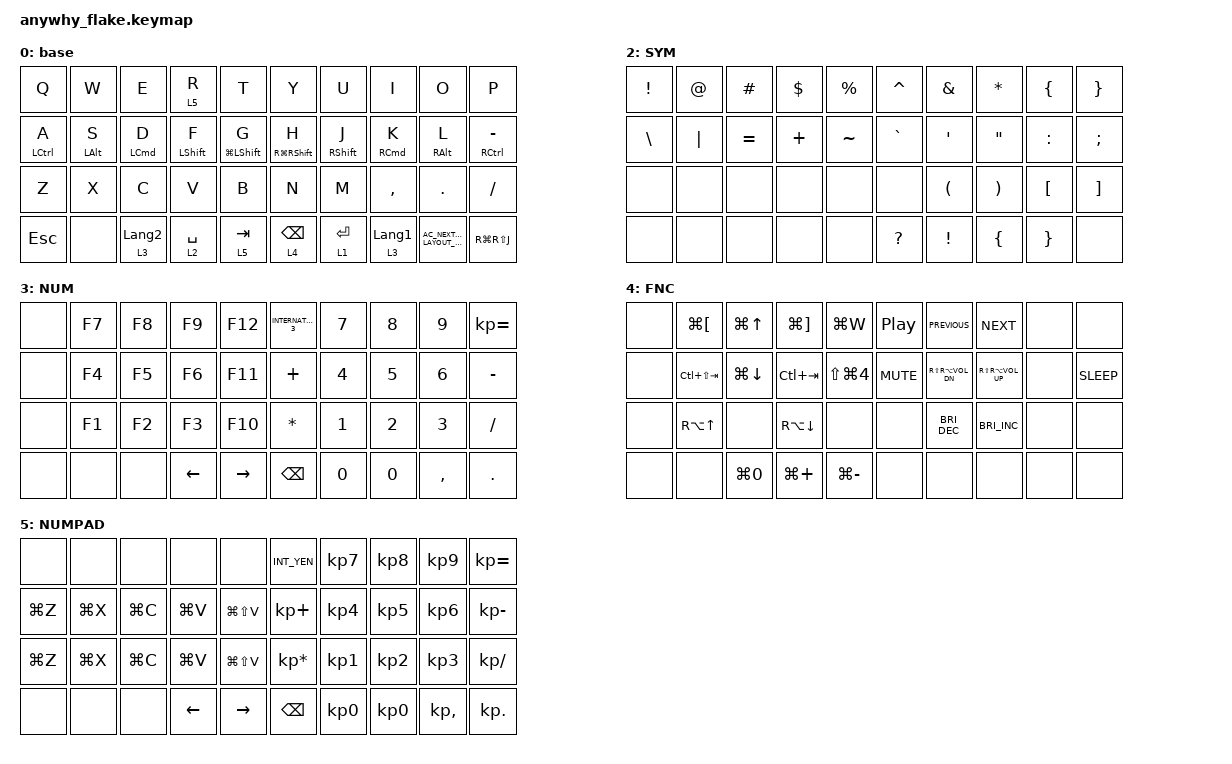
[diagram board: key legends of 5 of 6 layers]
#include <behaviors.dtsi>
#include <dt-bindings/zmk/bt.h>
#include <dt-bindings/zmk/keys.h>
#include <dt-bindings/zmk/outputs.h>

/ {
    combos {
        compatible = "zmk,combos";

        combo_ctrl_en {
            bindings = <&enenter>;
            key-positions = <16 18>;
            layers = <0>;
        };

        combo_caps {
            bindings = <&caps_word>;
            key-positions = <13 16>;
            layers = <0>;
        };

        combo_jp {
            bindings = <&kp LANGUAGE_1>;
            key-positions = <16 17>;
            layers = <0>;
        };

        combo_en {
            bindings = <&kp LANGUAGE_2>;
            key-positions = <12 13>;
            layers = <0>;
        };

        combo_src {
            bindings = <&combo_src>;
            key-positions = <34 35>;
            layers = <0>;
        };

        bt_0 {
            bindings = <&bt_0>;
            key-positions = <32 37>;
            layers = <0>;
        };

        bt_1 {
            bindings = <&bt_1>;
            key-positions = <31 38>;
            layers = <0>;
        };

        bt_2 {
            bindings = <&bt_2>;
            key-positions = <30 39>;
            layers = <0>;
        };

        bt_clr {
            bindings = <&bt BT_CLR>;
            key-positions = <20 29>;
            layers = <0>;
        };
    };

    macros {
        bt_0: bt_0 {
            compatible = "zmk,behavior-macro";
            #binding-cells = <0>;
            bindings = <&out OUT_BLE &bt BT_SEL 0>;
            label = "BT_0";
        };

        bt_1: bt_1 {
            compatible = "zmk,behavior-macro";
            #binding-cells = <0>;
            bindings = <&out OUT_BLE &bt BT_SEL 1>;
            label = "BT_1";
        };

        bt_2: bt_2 {
            compatible = "zmk,behavior-macro";
            #binding-cells = <0>;
            bindings = <&out OUT_BLE &bt BT_SEL 2>;
            label = "BT_2";
        };

        combo_src: combo_src {
            compatible = "zmk,behavior-macro";
            #binding-cells = <0>;
            bindings = <&kp KP_NUMBER_5 &kp KP_NUMBER_7 &kp KP_NUMBER_0 &kp KP_NUMBER_4>;
            label = "COMBO_SRC";
        };

        enenter: enenter {
            compatible = "zmk,behavior-macro";
            #binding-cells = <0>;
            bindings = <&kp LC(SEMICOLON)>;
            label = "ENENTER";
        };
    };

    behaviors {
        lp: lp {
            compatible = "zmk,behavior-hold-tap";
            label = "LP";
            bindings = <&mo>, <&kp>;

            #binding-cells = <2>;
            tapping-term-ms = <160>;
            quick-tap-ms = <105>;
        };

        cm: cm {
            compatible = "zmk,behavior-hold-tap";
            label = "CM";
            bindings = <&kp>, <&kp>;

            #binding-cells = <2>;
            tapping-term-ms = <160>;
            quick-tap-ms = <105>;
            flavor = "tap-preferred";
        };

        high_lp: high_lp {
            compatible = "zmk,behavior-hold-tap";
            label = "HIGH_LP";
            bindings = <&mo>, <&kp>;

            #binding-cells = <2>;
            tapping-term-ms = <160>;
            quick-tap-ms = <105>;
            flavor = "tap-preferred";
        };
    };

    keymap {
        compatible = "zmk,keymap";

        base {
            bindings = <
&kp Q        &kp W       &kp E             &high_lp 5 R  &kp T                 &kp Y            &kp U        &kp I                &kp O                                 &kp P
&cm LCTRL A  &cm LALT S  &cm LCMD D        &cm LSHFT F   &cm LG(LEFT_SHIFT) G  &cm RG(RSHFT) H  &cm RSHFT J  &cm RIGHT_COMMAND K  &cm RALT L                            &cm RCTRL MINUS
&kp Z        &kp X       &kp C             &kp V         &kp B                 &kp N            &kp M        &kp COMMA            &kp DOT                               &kp FSLH
&kp ESC      &none       &lp 3 LANGUAGE_2  &lp 2 SPACE   &lp 5 TAB             &lp 4 BACKSPACE  &lp 1 ENTER  &lp 3 LANGUAGE_1     &kp C_AC_NEXT_KEYBOARD_LAYOUT_SELECT  &kp RG(RS(J))
            >;
        };

        nav {
            label = "NAV";
            bindings = <
&none        &kp HOME        &kp UP_ARROW    &kp END          &kp LA(LS(TAB))  &none      &none      &none     &none     &none
&kp LG(TAB)  &kp LEFT_ARROW  &kp DOWN_ARROW  &kp RIGHT_ARROW  &kp LA(TAB)      &kp RCTRL  &kp RSHFT  &kp RGUI  &kp RALT  &kp RCTRL
&kp LG(Z)    &kp LG(X)       &kp LG(C)       &kp LG(V)        &kp LG(LS(V))    &none      &none      &none     &none     &none
&none        &none           &none           &kp SPACE        &kp TAB          &none      &kp RSHFT  &none     &none
            >;
        };

        sym {
            label = "SYM";
            bindings = <
&kp EXCL  &kp AT    &kp HASH   &kp DLLR  &kp PRCNT  &kp CARET     &kp AMPS  &kp STAR  &kp LBRC   &kp RBRC
&kp BSLH  &kp PIPE  &kp EQUAL  &kp PLUS  &kp TILDE  &kp GRAVE     &kp SQT   &kp DQT   &kp COLON  &kp SEMI
&none     &none     &none      &none     &none      &none         &kp LPAR  &kp RPAR  &kp LBKT   &kp RBKT
&none     &none     &none      &none     &none      &kp QUESTION  &kp EXCL  &kp LBRC  &kp RBRC   &none
            >;
        };

        num {
            label = "NUM";
            bindings = <
&none  &kp F7  &kp F8  &kp F9    &kp F12    &kp INTERNATIONAL_3  &kp N7        &kp N8  &kp N9     &kp KP_EQUAL
&none  &kp F4  &kp F5  &kp F6    &kp F11    &kp PLUS             &kp N4        &kp N5  &kp N6     &kp MINUS
&none  &kp F1  &kp F2  &kp F3    &kp F10    &kp STAR             &kp N1        &kp N2  &kp N3     &kp FSLH
&none  &none   &none   &kp LEFT  &kp RIGHT  &kp BACKSPACE        &kp NUMBER_0  &kp N0  &kp COMMA  &kp PERIOD
            >;
        };

        fnc {
            label = "FNC";
            bindings = <
&none  &kp LG(LEFT_BRACKET)  &kp LG(UP_ARROW)    &kp LG(RIGHT_BRACKET)  &kp LG(W)       &kp C_PP    &kp C_PREVIOUS        &kp C_NEXT            &none  &none
&none  &kp LC(LS(TAB))       &kp LG(DOWN_ARROW)  &kp LC(TAB)            &kp LS(LG(N4))  &kp K_MUTE  &kp RS(RA(C_VOL_DN))  &kp RS(RA(C_VOL_UP))  &none  &kp C_SLEEP
&none  &kp RA(UP)            &none               &kp RA(DOWN)           &none           &none       &kp C_BRI_DEC         &kp C_BRI_INC         &none  &none
&none  &none                 &kp LG(N0)          &kp LG(PLUS)           &kp LG(MINUS)   &none       &none                 &none                 &none  &none
            >;
        };

        numpad_cpp {
            label = "NUMPAD";
            bindings = <
&none      &none      &none      &none      &none          &kp INT_YEN      &kp KP_NUMBER_7  &kp KP_NUMBER_8  &kp KP_NUMBER_9  &kp KP_EQUAL
&kp LG(Z)  &kp LG(X)  &kp LG(C)  &kp LG(V)  &kp LG(LS(V))  &kp KP_PLUS      &kp KP_NUMBER_4  &kp KP_NUMBER_5  &kp KP_NUMBER_6  &kp KP_MINUS
&kp LG(Z)  &kp LG(X)  &kp LG(C)  &kp LG(V)  &kp LG(LS(V))  &kp KP_ASTERISK  &kp KP_NUMBER_1  &kp KP_NUMBER_2  &kp KP_N3        &kp KP_DIVIDE
&none      &none      &none      &kp LEFT   &kp RIGHT      &kp BACKSPACE    &kp KP_NUMBER_0  &kp KP_NUMBER_0  &kp KP_COMMA     &kp KP_DOT
            >;
        };
    };
};
